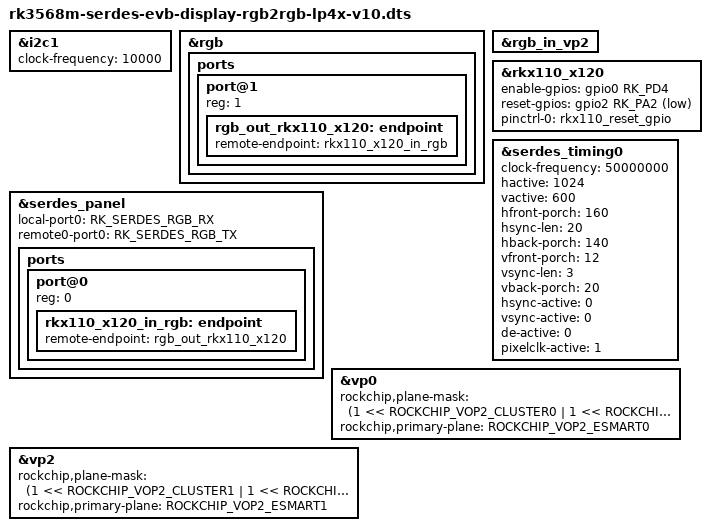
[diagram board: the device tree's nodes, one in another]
// SPDX-License-Identifier: (GPL-2.0+ OR MIT)
/*
 * Copyright (c) 2022 Rockchip Electronics Co., Ltd.
 *
 */

#include <dt-bindings/display/rockchip_vop.h>
#include "rk3568m-serdes-evb-lp4x-v10.dtsi"
#include "rk3568-android.dtsi"

&i2c1 {
	status = "okay";
	clock-frequency = <10000>;
};

&rgb {
	status = "okay";

	ports {
		#address-cells = <1>;
		#size-cells = <0>;

		port@1 {
			reg = <1>;
			rgb_out_rkx110_x120: endpoint {
				remote-endpoint = <&rkx110_x120_in_rgb>;
			};
		};
	};
};

&rgb_in_vp2 {
	status = "okay";
};

&rkx110_x120 {
		enable-gpios = <&gpio0 RK_PD4 GPIO_ACTIVE_HIGH>;
		reset-gpios = <&gpio2 RK_PA2 GPIO_ACTIVE_LOW>;
		pinctrl-names = "default";
		pinctrl-0 = <&rkx110_reset_gpio>;
};

&serdes_timing0 {
	clock-frequency = <50000000>;
	hactive = <1024>;
	vactive = <600>;
	hfront-porch = <160>;
	hsync-len = <20>;
	hback-porch = <140>;
	vfront-porch = <12>;
	vsync-len = <3>;
	vback-porch = <20>;
	hsync-active = <0>;
	vsync-active = <0>;
	de-active = <0>;
	pixelclk-active = <1>;
};

&serdes_panel {
	local-port0 = <RK_SERDES_RGB_RX>;
	remote0-port0 = <RK_SERDES_RGB_TX>;

	ports {
		#address-cells = <1>;
		#size-cells = <0>;

		port@0 {
			reg = <0>;
			rkx110_x120_in_rgb: endpoint {
				remote-endpoint = <&rgb_out_rkx110_x120>;
			};
		};
	};
};

/* vp0 for HDMI, vp2 for rgb */
&vp0 {
	rockchip,plane-mask = <(1 << ROCKCHIP_VOP2_CLUSTER0 | 1 << ROCKCHIP_VOP2_ESMART0 |
				1 << ROCKCHIP_VOP2_SMART0)>;
	rockchip,primary-plane = <ROCKCHIP_VOP2_ESMART0>;
};

&vp2 {
	rockchip,plane-mask = <(1 << ROCKCHIP_VOP2_CLUSTER1 | 1 << ROCKCHIP_VOP2_ESMART1 |
				1 << ROCKCHIP_VOP2_SMART1)>;
	rockchip,primary-plane = <ROCKCHIP_VOP2_ESMART1>;
};

